# ATxmega128A1 device description
Architecture: AVR8_XMEGA; Family: AVR XMEGA
Registers are 8-bit, access not given, no defined reset value unless marked. A register's access mark holds for its fields unless they carry their own. Offsets are from the block's base; [hi:lo] are bit positions; {n}, {i} and the like mark numbered series; 'fields as' and 'values as' point back to an identical list.

## NVM_PROD_SIGNATURES — Production Signatures
Instances: PROD_SIGNATURES 0x00 in prod_signatures
0x00 RCOSC2M — RCOSC 2MHz Calibration Value
0x02 RCOSC32K — RCOSC 32kHz Calibration Value
0x03 RCOSC32M — RCOSC 32MHz Calibration Value
{0x8+i} LOTNUM{i} (i=0..5) — Lot Number Byte {i}, ASCII
0x10 WAFNUM — Wafer Number
0x12 COORDX0 — Wafer Coordinate X Byte 0
0x13 COORDX1 — Wafer Coordinate X Byte 1
0x14 COORDY0 — Wafer Coordinate Y Byte 0
0x15 COORDY1 — Wafer Coordinate Y Byte 1
0x20 ADCACAL0 — ADCA Calibration Byte 0
0x21 ADCACAL1 — ADCA Calibration Byte 1
0x24 ADCBCAL0 — ADCB Calibration Byte 0
0x25 ADCBCAL1 — ADCB Calibration Byte 1
0x2E TEMPSENSE0 — Temperature Sensor Calibration Byte 0
0x2F TEMPSENSE1 — Temperature Sensor Calibration Byte 0
0x30 DACAOFFCAL — DACA Calibration Byte 0
0x31 DACAGAINCAL — DACA Calibration Byte 1
0x32 DACBOFFCAL — DACB Calibration Byte 0
0x33 DACBGAINCAL — DACB Calibration Byte 1

## AC — Analog Comparator
Instances: ACA 0x0380, ACB 0x0390
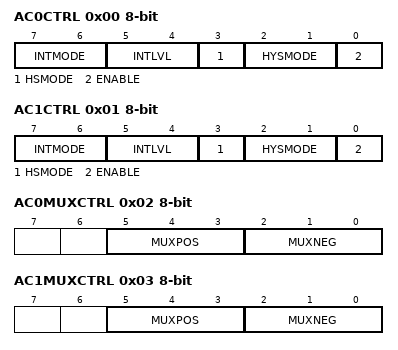
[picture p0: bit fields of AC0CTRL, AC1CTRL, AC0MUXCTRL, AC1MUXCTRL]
0x00 AC0CTRL — Analog Comparator 0 Control
  [7:6] INTMODE — Interrupt Mode
    0=BOTHEDGES (Interrupt on both edges); 2=FALLING (Interrupt on falling edge); 3=RISING (Interrupt on rising edge)
  [5:4] INTLVL — Interrupt Level
    0=OFF (Interrupt disabled); 1=LO (Low level); 2=MED (Medium level); 3=HI (High level)
  [3] HSMODE — High-speed Mode
  [2:1] HYSMODE — Hysteresis Mode
    0=NO (No hysteresis); 1=SMALL (Small hysteresis); 2=LARGE (Large hysteresis)
  [0] ENABLE
0x01 AC1CTRL — Analog Comparator 1 Control
  fields as AC0CTRL
0x02 AC0MUXCTRL — Analog Comparator 0 MUX Control
  [5:3] MUXPOS — MUX Positive Input
    {v}=PIN{v} (v=0..6); 7=DAC (DAC output)
  [2:0] MUXNEG — MUX Negative Input
    0=PIN0; 1=PIN1; 2=PIN3; 3=PIN5; 4=PIN7; 5=DAC (DAC output); 6=BANDGAP (Bandgap Reference); 7=SCALER (Internal voltage scaler)
0x03 AC1MUXCTRL — Analog Comparator 1 MUX Control
  fields as AC0MUXCTRL
0x04 CTRLA — Control Register A
  [0] AC0OUT — Analog Comparator 0 Output Enable
0x05 CTRLB — Control Register B
  [5:0] SCALEFAC — VCC Voltage Scaler Factor
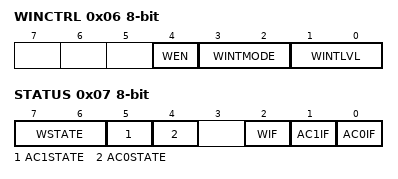
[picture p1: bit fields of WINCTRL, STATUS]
0x06 WINCTRL — Window Mode Control
  [4] WEN — Window Mode Enable
  [3:2] WINTMODE — Window Interrupt Mode
    0=ABOVE (Interrupt on above window); 1=INSIDE (Interrupt on inside window); 2=BELOW (Interrupt on below window); 3=OUTSIDE (Interrupt on outside window)
  [1:0] WINTLVL — Window Interrupt Level
    0=OFF (Interrupt disabled); 1=LO (Low priority); 2=MED (Medium priority); 3=HI (High priority)
0x07 STATUS
  [7:6] WSTATE — Window Mode State
    0=ABOVE (Signal above window); 1=INSIDE (Signal inside window); 2=BELOW (Signal below window)
  [5] AC1STATE — Analog Comparator 1 State
  [4] AC0STATE — Analog Comparator 0 State
  [2] WIF — Window Mode Interrupt Flag
  [1] AC1IF — Analog Comparator 1 Interrupt Flag
  [0] AC0IF — Analog Comparator 0 Interrupt Flag

## DAC — Digital-to-Analog Converter
Instances: DACA 0x0300, DACB 0x0320
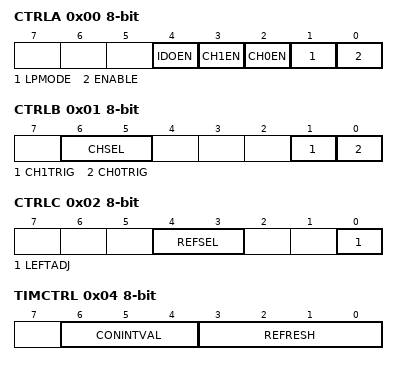
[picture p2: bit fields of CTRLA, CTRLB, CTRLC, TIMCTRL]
0x00 CTRLA — Control Register A
  [4] IDOEN — Internal Output Enable
  [3] CH1EN — Channel 1 Output Enable
  [2] CH0EN — Channel 0 Output Enable
  [1] LPMODE — Low Power Mode
  [0] ENABLE
0x01 CTRLB — Control Register B
  [6:5] CHSEL — Channel Select
    0=SINGLE (Single channel operation (Channel A only)); 2=DUAL (Dual channel operation (S/H on both channels))
  [1] CH1TRIG — Channel 1 Event Trig Enable
  [0] CH0TRIG — Channel 0 Event Trig Enable
0x02 CTRLC — Control Register C
  [4:3] REFSEL — Reference Select
    0=INT1V (Internal 1V); 1=AVCC (Analog supply voltage); 2=AREFA (External reference on AREF on PORTA); 3=AREFB (External reference on AREF on PORTB)
  [0] LEFTADJ — Left-adjust Result
0x03 EVCTRL — Event Input Control
  [2:0] EVSEL — Event Input Selection
    {v}=Event Channel {v} (v=0..7)
0x04 TIMCTRL — Timing Control
  [6:4] CONINTVAL — Conversion Intercal
    0=1CLK (1 CLK / 2 CLK in S/H mode); 1=2CLK (2 CLK / 3 CLK in S/H mode); 2=4CLK (4 CLK / 6 CLK in S/H mode); 3=8CLK (8 CLK / 12 CLK in S/H mode); 4=16CLK (16 CLK / 24 CLK in S/H mode); 5=32CLK (32 CLK / 48 CLK in S/H mode); 6=64CLK (64 CLK / 96 CLK in S/H mode); 7=128CLK (128 CLK / 192 CLK in S/H mode)
  [3:0] REFRESH — Refresh Timing Control
    0=16CLK; 1=32CLK; 2=64CLK; 3=128CLK; 4=256CLK; 5=512CLK; 6=1024CLK; 7=2048CLK; 8=4096CLK; 9=8192CLK; 10=16384CLK; 11=32768CLK; 12=65536CLK; 15=OFF (Auto refresh OFF)
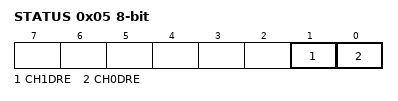
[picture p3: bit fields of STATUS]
0x05 STATUS
  [1] CH1DRE — Channel 1 Data Register Empty
  [0] CH0DRE — Channel 0 Data Register Empty
0x08 GAINCAL — Gain Calibration
  [6:0] GAINCAL
0x09 OFFSETCAL — Offset Calibration
  [6:0] OFFSETCAL
0x18 CH0DATA 16-bit — Channel 0 Data
0x1A CH1DATA 16-bit — Channel 1 Data
